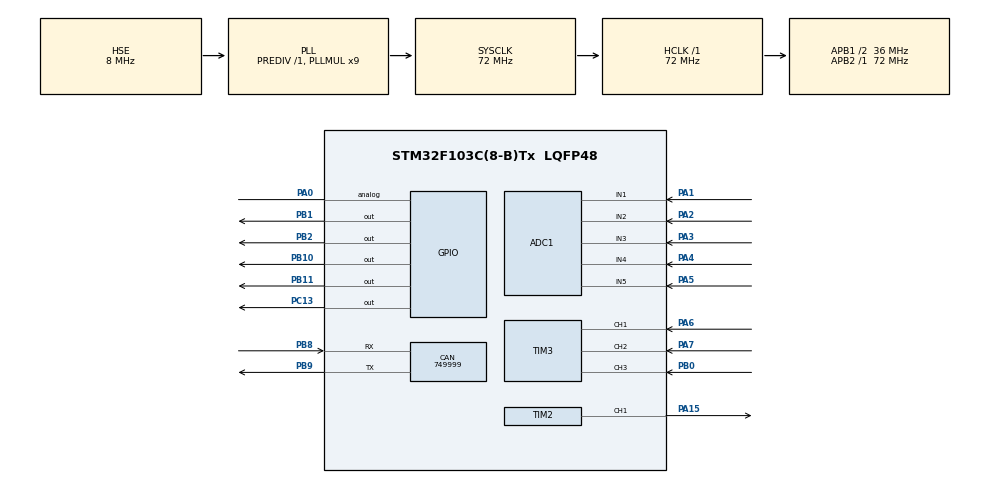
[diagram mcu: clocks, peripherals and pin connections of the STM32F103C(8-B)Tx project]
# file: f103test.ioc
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ADC1.Channel-0\#ChannelRegularConversion=ADC_CHANNEL_1
ADC1.NbrOfConversionFlag=1
ADC1.Rank-0\#ChannelRegularConversion=1
ADC1.SamplingTime-0\#ChannelRegularConversion=ADC_SAMPLETIME_1CYCLE_5
ADC1.master=1
CAN.BS1=CAN_BS1_1TQ
CAN.BS2=CAN_BS2_1TQ
CAN.CalculateBaudRate=749999
CAN.CalculateTimeBit=1333
CAN.CalculateTimeQuantum=444.44444444444446
Dma.Request0=TIM1_UP
Dma.TIM1_UP.0.Direction=DMA_MEMORY_TO_PERIPH
Dma.TIM1_UP.0.Instance=DMA1_Channel5
Dma.TIM1_UP.0.MemDataAlignment=DMA_MDATAALIGN_HALFWORD
Dma.TIM1_UP.0.MemInc=DMA_MINC_ENABLE
Dma.TIM1_UP.0.Mode=DMA_NORMAL
Dma.TIM1_UP.0.PeriphDataAlignment=DMA_PDATAALIGN_HALFWORD
Dma.TIM1_UP.0.PeriphInc=DMA_PINC_DISABLE
Dma.TIM1_UP.0.Priority=DMA_PRIORITY_VERY_HIGH
FREERTOS.Tasks01=defaultTask,24,128,StartDefaultTask,Default,NULL,Dynamic,NULL,NULL;blinky,8,128,StartBlinky,Default,NULL,Dynamic,NULL,NULL
FREERTOS.configTOTAL_HEAP_SIZE=4096
FREERTOS.configUSE_NEWLIB_REENTRANT=1
Mcu.Family=STM32F1
Mcu.Name=STM32F103C(8-B)Tx
Mcu.Package=LQFP48
NVIC.DMA1_Channel5_IRQn=true\:5\:0\:false\:false\:true\:true\:false\:true\:true
NVIC.PriorityGroup=NVIC_PRIORITYGROUP_4
NVIC.TIM4_IRQn=true\:15\:0\:false\:false\:true\:false\:false\:true\:true
NVIC.TimeBase=TIM4_IRQn
NVIC.TimeBaseIP=TIM4
NVIC.USB_LP_CAN1_RX0_IRQn=true\:5\:0\:false\:false\:true\:true\:false\:true\:true
PA0-WKUP.Signal=GPIO_Analog
PA1.Signal=ADCx_IN1
PA13.Mode=Trace_Asynchronous_SW
PA13.Signal=SYS_JTMS-SWDIO
PA14.Mode=Trace_Asynchronous_SW
PA14.Signal=SYS_JTCK-SWCLK
PA15.Signal=S_TIM2_CH1_ETR
PA2.Signal=ADCx_IN2
PA3.Signal=ADCx_IN3
PA4.Signal=ADCx_IN4
PA5.Signal=ADCx_IN5
PA6.Signal=S_TIM3_CH1
PA7.Signal=S_TIM3_CH2
PB0.Signal=S_TIM3_CH3
PB1.Signal=GPIO_Output
PB10.Signal=GPIO_Output
PB11.Signal=GPIO_Output
PB2.Signal=GPIO_Output
PB3.Mode=Trace_Asynchronous_SW
PB3.Signal=SYS_JTDO-TRACESWO
PB8.Mode=CAN_Activate
PB8.Signal=CAN_RX
PB9.Mode=CAN_Activate
PB9.Signal=CAN_TX
PC13-TAMPER-RTC.Signal=GPIO_Output
PC14-OSC32_IN.Mode=LSE-External-Oscillator
PC14-OSC32_IN.Signal=RCC_OSC32_IN
PC15-OSC32_OUT.Mode=LSE-External-Oscillator
PC15-OSC32_OUT.Signal=RCC_OSC32_OUT
PD0-OSC_IN.Mode=HSE-External-Oscillator
PD0-OSC_IN.Signal=RCC_OSC_IN
PD1-OSC_OUT.Mode=HSE-External-Oscillator
PD1-OSC_OUT.Signal=RCC_OSC_OUT
ProjectManager.HeapSize=0x200
ProjectManager.StackSize=0x400
ProjectManager.TargetToolchain=STM32CubeIDE
RCC.ADCPresc=RCC_ADCPCLK2_DIV6
RCC.AHBFreq_Value=72000000
RCC.APB1CLKDivider=RCC_HCLK_DIV2
RCC.APB1Freq_Value=36000000
RCC.APB1TimFreq_Value=72000000
RCC.APB2Freq_Value=72000000
RCC.APB2TimFreq_Value=72000000
RCC.HCLKFreq_Value=72000000
RCC.PLLMUL=RCC_PLL_MUL9
RCC.PLLSourceVirtual=RCC_PLLSOURCE_HSE
RCC.SYSCLKFreq_VALUE=72000000
RCC.SYSCLKSource=RCC_SYSCLKSOURCE_PLLCLK
RCC.USBFreq_Value=48000000
RCC.USBPrescaler=RCC_USBCLKSOURCE_PLL_DIV1_5
SH.ADCx_IN1.0=ADC1_IN1,IN1
SH.ADCx_IN2.0=ADC1_IN2,IN2
SH.ADCx_IN3.0=ADC1_IN3,IN3
SH.ADCx_IN4.0=ADC1_IN4,IN4
SH.ADCx_IN5.0=ADC1_IN5,IN5
SH.S_TIM2_CH1_ETR.0=TIM2_CH1,PWM Generation1 CH1
SH.S_TIM3_CH1.0=TIM3_CH1,Xored_Inputs_Hall_Sensor_Interface
SH.S_TIM3_CH2.0=TIM3_CH2,Xored_Inputs_Hall_Sensor_Interface
SH.S_TIM3_CH3.0=TIM3_CH3,Xored_Inputs_Hall_Sensor_Interface
TIM2.Channel-PWM\ Generation1\ CH1=TIM_CHANNEL_1
VP_FREERTOS_VS_CMSIS_V2.Mode=CMSIS_V2
VP_SYS_VS_tim4.Mode=TIM4
VP_TIM1_VS_OPM.Mode=OPM_bit
board=custom

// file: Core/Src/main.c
/* USER CODE BEGIN Header */
/**
  ******************************************************************************
  * @file           : main.c
  * @brief          : Main program body
  ******************************************************************************
  * @attention
  *
  * Copyright (c) 2023 STMicroelectronics.
  * All rights reserved.
  *
  * This software is licensed under terms that can be found in the LICENSE file
  * in the root directory of this software component.
  * If no LICENSE file comes with this software, it is provided AS-IS.
  *
  ******************************************************************************
  */
/* USER CODE END Header */
#include "main.h"
#include "cmsis_os.h"

 ADC_HandleTypeDef hadc1;

CAN_HandleTypeDef hcan;

TIM_HandleTypeDef htim1;
TIM_HandleTypeDef htim2;
TIM_HandleTypeDef htim3;
DMA_HandleTypeDef hdma_tim1_up;

/* Definitions for defaultTask */
osThreadId_t defaultTaskHandle;
const osThreadAttr_t defaultTask_attributes = {
  .name = "defaultTask",
  .stack_size = 128 * 4,
  .priority = (osPriority_t) osPriorityNormal,
};
/* Definitions for blinky */
osThreadId_t blinkyHandle;
const osThreadAttr_t blinky_attributes = {
  .name = "blinky",
  .stack_size = 128 * 4,
  .priority = (osPriority_t) osPriorityLow,
};

void SystemClock_Config(void);
static void MX_GPIO_Init(void);
static void MX_DMA_Init(void);
static void MX_CAN_Init(void);
static void MX_TIM1_Init(void);
static void MX_ADC1_Init(void);
static void MX_TIM2_Init(void);
static void MX_TIM3_Init(void);
void StartDefaultTask(void *argument);
void StartBlinky(void *argument);

int main(void)
{

  /* MCU Configuration--------------------------------------------------------*/

  /* Reset of all peripherals, Initializes the Flash interface and the Systick. */
  HAL_Init();

  /* Configure the system clock */
  SystemClock_Config();

  /* Initialize all configured peripherals */
  MX_GPIO_Init();
  MX_DMA_Init();
  MX_CAN_Init();
  MX_TIM1_Init();
  MX_ADC1_Init();
  MX_TIM2_Init();
  MX_TIM3_Init();

  /* Init scheduler */
  osKernelInitialize();

  /* Create the thread(s) */
  /* creation of defaultTask */
  defaultTaskHandle = osThreadNew(StartDefaultTask, NULL, &defaultTask_attributes);

  /* creation of blinky */
  blinkyHandle = osThreadNew(StartBlinky, NULL, &blinky_attributes);

  /* Start scheduler */
  osKernelStart();

  /* We should never get here as control is now taken by the scheduler */
  /* Infinite loop */
  while (1)
  {

  }
}

void SystemClock_Config(void)
{
  RCC_OscInitTypeDef RCC_OscInitStruct = {0};
  RCC_ClkInitTypeDef RCC_ClkInitStruct = {0};
  RCC_PeriphCLKInitTypeDef PeriphClkInit = {0};

  /** Initializes the RCC Oscillators according to the specified parameters
  * in the RCC_OscInitTypeDef structure.
  */
  RCC_OscInitStruct.OscillatorType = RCC_OSCILLATORTYPE_HSE;
  RCC_OscInitStruct.HSEState = RCC_HSE_ON;
  RCC_OscInitStruct.HSEPredivValue = RCC_HSE_PREDIV_DIV1;
  RCC_OscInitStruct.HSIState = RCC_HSI_ON;
  RCC_OscInitStruct.PLL.PLLState = RCC_PLL_ON;
  RCC_OscInitStruct.PLL.PLLSource = RCC_PLLSOURCE_HSE;
  RCC_OscInitStruct.PLL.PLLMUL = RCC_PLL_MUL9;
  if (HAL_RCC_OscConfig(&RCC_OscInitStruct) != HAL_OK)
  {
    Error_Handler();
  }

  /** Initializes the CPU, AHB and APB buses clocks
  */
  RCC_ClkInitStruct.ClockType = RCC_CLOCKTYPE_HCLK|RCC_CLOCKTYPE_SYSCLK
                              |RCC_CLOCKTYPE_PCLK1|RCC_CLOCKTYPE_PCLK2;
  RCC_ClkInitStruct.SYSCLKSource = RCC_SYSCLKSOURCE_PLLCLK;
  RCC_ClkInitStruct.AHBCLKDivider = RCC_SYSCLK_DIV1;
  RCC_ClkInitStruct.APB1CLKDivider = RCC_HCLK_DIV2;
  RCC_ClkInitStruct.APB2CLKDivider = RCC_HCLK_DIV1;

  if (HAL_RCC_ClockConfig(&RCC_ClkInitStruct, FLASH_LATENCY_2) != HAL_OK)
  {
    Error_Handler();
  }
  PeriphClkInit.PeriphClockSelection = RCC_PERIPHCLK_ADC;
  PeriphClkInit.AdcClockSelection = RCC_ADCPCLK2_DIV6;
  if (HAL_RCCEx_PeriphCLKConfig(&PeriphClkInit) != HAL_OK)
  {
    Error_Handler();
  }
}

static void MX_ADC1_Init(void)
{

  ADC_ChannelConfTypeDef sConfig = {0};

  /** Common config
  */
  hadc1.Instance = ADC1;
  hadc1.Init.ScanConvMode = ADC_SCAN_DISABLE;
  hadc1.Init.ContinuousConvMode = DISABLE;
  hadc1.Init.DiscontinuousConvMode = DISABLE;
  hadc1.Init.ExternalTrigConv = ADC_SOFTWARE_START;
  hadc1.Init.DataAlign = ADC_DATAALIGN_RIGHT;
  hadc1.Init.NbrOfConversion = 1;
  if (HAL_ADC_Init(&hadc1) != HAL_OK)
  {
    Error_Handler();
  }

  /** Configure Regular Channel
  */
  sConfig.Channel = ADC_CHANNEL_1;
  sConfig.Rank = ADC_REGULAR_RANK_1;
  sConfig.SamplingTime = ADC_SAMPLETIME_1CYCLE_5;
  if (HAL_ADC_ConfigChannel(&hadc1, &sConfig) != HAL_OK)
  {
    Error_Handler();
  }

}

static void MX_CAN_Init(void)
{

  hcan.Instance = CAN1;
  hcan.Init.Prescaler = 16;
  hcan.Init.Mode = CAN_MODE_NORMAL;
  hcan.Init.SyncJumpWidth = CAN_SJW_1TQ;
  hcan.Init.TimeSeg1 = CAN_BS1_1TQ;
  hcan.Init.TimeSeg2 = CAN_BS2_1TQ;
  hcan.Init.TimeTriggeredMode = DISABLE;
  hcan.Init.AutoBusOff = DISABLE;
  hcan.Init.AutoWakeUp = DISABLE;
  hcan.Init.AutoRetransmission = DISABLE;
  hcan.Init.ReceiveFifoLocked = DISABLE;
  hcan.Init.TransmitFifoPriority = DISABLE;
  if (HAL_CAN_Init(&hcan) != HAL_OK)
  {
    Error_Handler();
  }

}

static void MX_TIM1_Init(void)
{

  TIM_MasterConfigTypeDef sMasterConfig = {0};

  htim1.Instance = TIM1;
  htim1.Init.Prescaler = 0;
  htim1.Init.CounterMode = TIM_COUNTERMODE_UP;
  htim1.Init.Period = 65535;
  htim1.Init.ClockDivision = TIM_CLOCKDIVISION_DIV1;
  htim1.Init.RepetitionCounter = 0;
  htim1.Init.AutoReloadPreload = TIM_AUTORELOAD_PRELOAD_DISABLE;
  if (HAL_TIM_OnePulse_Init(&htim1, TIM_OPMODE_SINGLE) != HAL_OK)
  {
    Error_Handler();
  }
  sMasterConfig.MasterOutputTrigger = TIM_TRGO_RESET;
  sMasterConfig.MasterSlaveMode = TIM_MASTERSLAVEMODE_DISABLE;
  if (HAL_TIMEx_MasterConfigSynchronization(&htim1, &sMasterConfig) != HAL_OK)
  {
    Error_Handler();
  }

}

static void MX_TIM2_Init(void)
{

  TIM_MasterConfigTypeDef sMasterConfig = {0};
  TIM_OC_InitTypeDef sConfigOC = {0};

  htim2.Instance = TIM2;
  htim2.Init.Prescaler = 0;
  htim2.Init.CounterMode = TIM_COUNTERMODE_UP;
  htim2.Init.Period = 65535;
  htim2.Init.ClockDivision = TIM_CLOCKDIVISION_DIV1;
  htim2.Init.AutoReloadPreload = TIM_AUTORELOAD_PRELOAD_DISABLE;
  if (HAL_TIM_PWM_Init(&htim2) != HAL_OK)
  {
    Error_Handler();
  }
  sMasterConfig.MasterOutputTrigger = TIM_TRGO_RESET;
  sMasterConfig.MasterSlaveMode = TIM_MASTERSLAVEMODE_DISABLE;
  if (HAL_TIMEx_MasterConfigSynchronization(&htim2, &sMasterConfig) != HAL_OK)
  {
    Error_Handler();
  }
  sConfigOC.OCMode = TIM_OCMODE_PWM1;
  sConfigOC.Pulse = 0;
  sConfigOC.OCPolarity = TIM_OCPOLARITY_HIGH;
  sConfigOC.OCFastMode = TIM_OCFAST_DISABLE;
  if (HAL_TIM_PWM_ConfigChannel(&htim2, &sConfigOC, TIM_CHANNEL_1) != HAL_OK)
  {
    Error_Handler();
  }
  HAL_TIM_MspPostInit(&htim2);

}

static void MX_TIM3_Init(void)
{

  TIM_HallSensor_InitTypeDef sConfig = {0};
  TIM_MasterConfigTypeDef sMasterConfig = {0};

  htim3.Instance = TIM3;
  htim3.Init.Prescaler = 0;
  htim3.Init.CounterMode = TIM_COUNTERMODE_UP;
  htim3.Init.Period = 65535;
  htim3.Init.ClockDivision = TIM_CLOCKDIVISION_DIV1;
  htim3.Init.AutoReloadPreload = TIM_AUTORELOAD_PRELOAD_DISABLE;
  sConfig.IC1Polarity = TIM_ICPOLARITY_RISING;
  sConfig.IC1Prescaler = TIM_ICPSC_DIV1;
  sConfig.IC1Filter = 0;
  sConfig.Commutation_Delay = 0;
  if (HAL_TIMEx_HallSensor_Init(&htim3, &sConfig) != HAL_OK)
  {
    Error_Handler();
  }
  sMasterConfig.MasterOutputTrigger = TIM_TRGO_OC2REF;
  sMasterConfig.MasterSlaveMode = TIM_MASTERSLAVEMODE_DISABLE;
  if (HAL_TIMEx_MasterConfigSynchronization(&htim3, &sMasterConfig) != HAL_OK)
  {
    Error_Handler();
  }

}

static void MX_DMA_Init(void)
{

  /* DMA controller clock enable */
  __HAL_RCC_DMA1_CLK_ENABLE();

  /* DMA interrupt init */
  /* DMA1_Channel5_IRQn interrupt configuration */
  HAL_NVIC_SetPriority(DMA1_Channel5_IRQn, 5, 0);
  HAL_NVIC_EnableIRQ(DMA1_Channel5_IRQn);

}

static void MX_GPIO_Init(void)
{
  GPIO_InitTypeDef GPIO_InitStruct = {0};

  /* GPIO Ports Clock Enable */
  __HAL_RCC_GPIOC_CLK_ENABLE();
  __HAL_RCC_GPIOD_CLK_ENABLE();
  __HAL_RCC_GPIOA_CLK_ENABLE();
  __HAL_RCC_GPIOB_CLK_ENABLE();

  /*Configure GPIO pin Output Level */
  HAL_GPIO_WritePin(GPIOC, GPIO_PIN_13, GPIO_PIN_RESET);

  /*Configure GPIO pin Output Level */
  HAL_GPIO_WritePin(GPIOB, GPIO_PIN_1|GPIO_PIN_2|GPIO_PIN_10|GPIO_PIN_11, GPIO_PIN_RESET);

  /*Configure GPIO pin : PC13 */
  GPIO_InitStruct.Pin = GPIO_PIN_13;
  GPIO_InitStruct.Mode = GPIO_MODE_OUTPUT_PP;
  GPIO_InitStruct.Pull = GPIO_NOPULL;
  GPIO_InitStruct.Speed = GPIO_SPEED_FREQ_LOW;
  HAL_GPIO_Init(GPIOC, &GPIO_InitStruct);

  /*Configure GPIO pin : PA0 */
  GPIO_InitStruct.Pin = GPIO_PIN_0;
  GPIO_InitStruct.Mode = GPIO_MODE_ANALOG;
  HAL_GPIO_Init(GPIOA, &GPIO_InitStruct);

  /*Configure GPIO pins : PB1 PB2 PB10 PB11 */
  GPIO_InitStruct.Pin = GPIO_PIN_1|GPIO_PIN_2|GPIO_PIN_10|GPIO_PIN_11;
  GPIO_InitStruct.Mode = GPIO_MODE_OUTPUT_PP;
  GPIO_InitStruct.Pull = GPIO_NOPULL;
  GPIO_InitStruct.Speed = GPIO_SPEED_FREQ_LOW;
  HAL_GPIO_Init(GPIOB, &GPIO_InitStruct);

}

void StartDefaultTask(void *argument)
{
  for(;;)
  {
    osDelay(1);
  }
}

void StartBlinky(void *argument)
{
  /* USER CODE BEGIN StartBlinky */
  /* Infinite loop */
  for(;;)
  {
    osDelay(100);
    GPIO_PinState s = HAL_GPIO_ReadPin(GPIOC, GPIO_PIN_13);
    HAL_GPIO_WritePin(GPIOC, GPIO_PIN_13, !s);
  }
  /* USER CODE END StartBlinky */
}

void HAL_TIM_PeriodElapsedCallback(TIM_HandleTypeDef *htim)
{
  if (htim->Instance == TIM4) {
    HAL_IncTick();
  }
}

void Error_Handler(void)
{
  __disable_irq();
  while (1)
  {
  }
}
